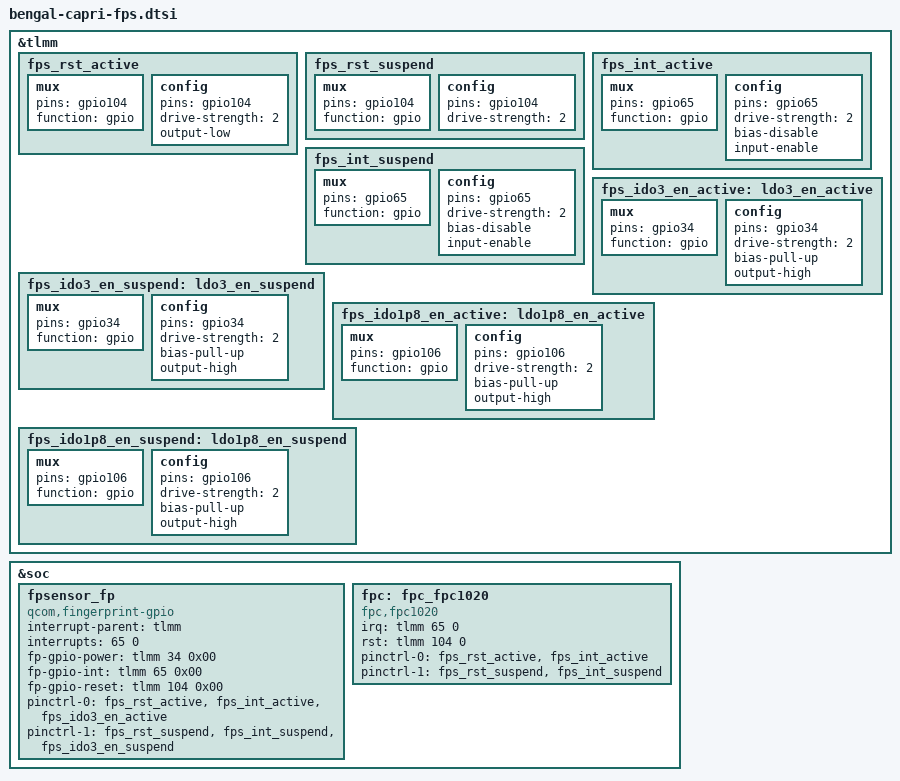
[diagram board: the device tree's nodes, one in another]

&tlmm {
	fps_rst_active: fps_rst_active {
		/* active state */
		mux {
			pins = "gpio104";
			function = "gpio";
		};

		config {
			pins = "gpio104";
			drive-strength = <2>; /* 2 MA */
			output-low;
		};
	};

	fps_rst_suspend: fps_rst_suspend {
		/* sleep state */
		mux {
			pins = "gpio104";
			function = "gpio";
		};

		config {
			pins = "gpio104";
			drive-strength = <2>; /* 2 MA */
		};
	};

	fps_int_active: fps_int_active {
		/* active state */
		mux {
			pins = "gpio65";
			function = "gpio";
		};

		config {
			pins = "gpio65";
			drive-strength = <2>; /* 2 MA */
			bias-disable;
			input-enable;
		};
	};

	fps_int_suspend: fps_int_suspend {
		/* sleep state */
		mux {
			pins = "gpio65";
			function = "gpio";
		};

		config {
			pins = "gpio65";
			drive-strength = <2>; /* 2 MA */
			bias-disable;
			input-enable;
		};
	};

	fps_ido3_en_active: ldo3_en_active {
		/* active state */
		mux {
			pins = "gpio34";
			function = "gpio";
		};

		config {
			pins = "gpio34";
			drive-strength = <2>; /* 2 MA */
			bias-pull-up;
			output-high;
		};
	};

	fps_ido3_en_suspend: ldo3_en_suspend {
		/* suspend state */
		mux {
			pins = "gpio34";
			function = "gpio";
		};

		config {
			pins = "gpio34";
			drive-strength = <2>; /* 2 MA */
			bias-pull-up;
			output-high;
		};
	};

	fps_ido1p8_en_active: ldo1p8_en_active {
		/* active state */
		mux {
			pins = "gpio106";
			function = "gpio";
		};

		config {
			pins = "gpio106";
			drive-strength = <2>; /* 2 MA */
			bias-pull-up;
			output-high;
		};
	};

	fps_ido1p8_en_suspend: ldo1p8_en_suspend {
		/* suspend state */
		mux {
			pins = "gpio106";
			function = "gpio";
		};

		config {
			pins = "gpio106";
			drive-strength = <2>; /* 2 MA */
			bias-pull-up;
			output-high;
		};
	};
};

&soc {
        fpsensor_fp {
                //status = "/chosen", "mmi,fps", "true";
                status = "ok";
                compatible = "qcom,fingerprint-gpio";
                interrupt-parent = <&tlmm>;
                interrupts = <65 0>;
                fp-gpio-power = <&tlmm 34 0x00>;
                fp-gpio-int    = <&tlmm 65 0x00>;
                fp-gpio-reset = <&tlmm 104 0x00>;
                pinctrl-names = "default", "suspend";
                pinctrl-0 = <&fps_rst_active &fps_int_active &fps_ido3_en_active>;
                pinctrl-1 = <&fps_rst_suspend &fps_int_suspend &fps_ido3_en_suspend>;
        };

	fpc: fpc_fpc1020 {
		compatible = "fpc,fpc1020";
		status = "ok";
		irq = <&tlmm 65 0>;
		rst = <&tlmm 104 0>;
		pinctrl-names = "default", "suspend";
		pinctrl-0 = <&fps_rst_active &fps_int_active>;
		pinctrl-1 = <&fps_rst_suspend &fps_int_suspend>;
	};
};
